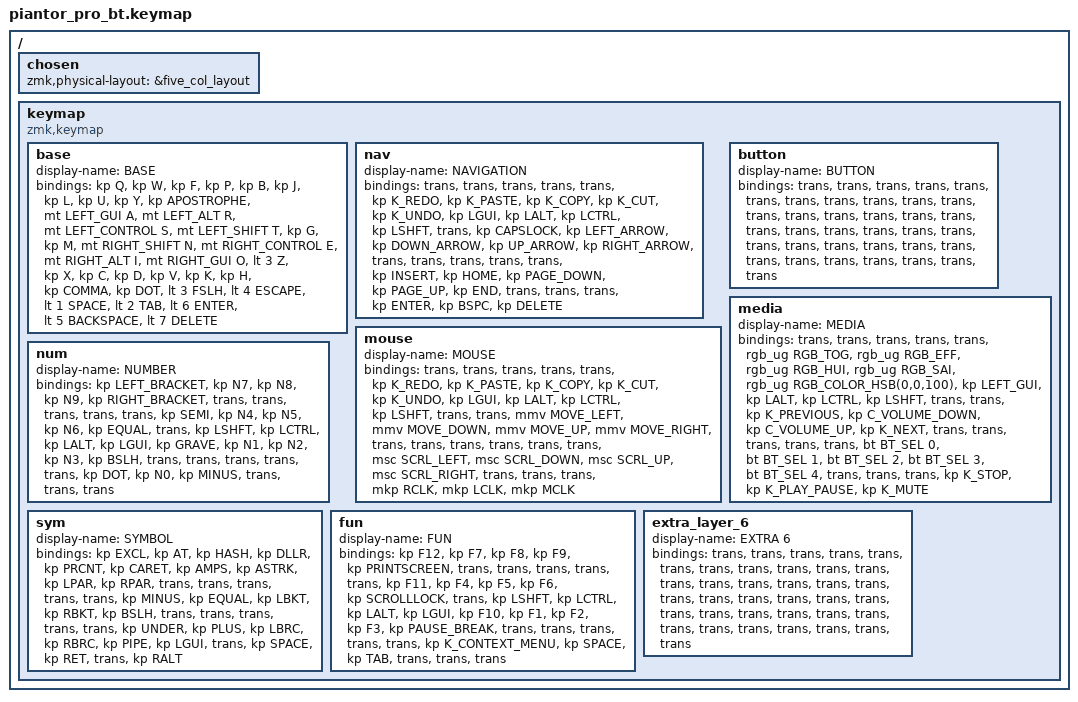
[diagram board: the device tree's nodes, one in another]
/*
 * Copyright (c) 2020 The ZMK Contributors
 *
 * SPDX-License-Identifier: MIT
 */

#include <behaviors.dtsi>
#include <dt-bindings/zmk/bt.h>
#include <dt-bindings/zmk/keys.h>
#include <dt-bindings/zmk/pointing.h>
#include <dt-bindings/zmk/rgb.h>

/ {
    chosen { zmk,physical-layout = &five_col_layout; };
};

/ {
    keymap {
        compatible = "zmk,keymap";

        base {
            display-name = "BASE";

            // --------------------------------------------------------------
            // |  Q  |  W  |  E  |  R  |  T  |  Y  |  U   |  I  |  O  |  P  |
            // |  A  |  S  |  D  |  F  |  G  |  H  |  J   |  K  |  L  |  ;  |
            // |  Z  |  X  |  C  |  V  |  B  |  N  |  M   |  ,  |  .  |  /  |
            //                    | GUI | LWR | SPC | ENT | RSE  | ALT |

            bindings = <
  &kp Q  &kp W  &kp F  &kp P  &kp B  &kp J  &kp L  &kp U  &kp Y  &kp APOSTROPHE      &mt LEFT_GUI A  &mt LEFT_ALT R  &mt LEFT_CONTROL S  &mt LEFT_SHIFT T  &kp G  &kp M  &mt RIGHT_SHIFT N  &mt RIGHT_CONTROL E  &mt RIGHT_ALT I  &mt RIGHT_GUI O      &lt 3 Z  &kp X  &kp C  &kp D  &kp V  &kp K  &kp H  &kp COMMA  &kp DOT  &lt 3 FSLH    &lt 4 ESCAPE  &lt 1 SPACE  &lt 2 TAB  &lt 6 ENTER  &lt 5 BACKSPACE  &lt 7 DELETE
            >;
        };

        nav {
            display-name = "NAVIGATION";
            bindings = <
  &trans  &trans  &trans  &trans  &trans  &kp K_REDO  &kp K_PASTE  &kp K_COPY  &kp K_CUT  &kp K_UNDO      &kp LGUI  &kp LALT  &kp LCTRL  &kp LSHFT  &trans  &kp CAPSLOCK  &kp LEFT_ARROW  &kp DOWN_ARROW  &kp UP_ARROW  &kp RIGHT_ARROW      &trans  &trans  &trans  &trans  &trans  &kp INSERT  &kp HOME  &kp PAGE_DOWN  &kp PAGE_UP  &kp END    &trans  &trans  &trans  &kp ENTER  &kp BSPC  &kp DELETE
            >;
        };

        mouse {
            display-name = "MOUSE";
            bindings = <
  &trans  &trans  &trans  &trans  &trans  &kp K_REDO  &kp K_PASTE  &kp K_COPY  &kp K_CUT  &kp K_UNDO      &kp LGUI  &kp LALT  &kp LCTRL  &kp LSHFT  &trans  &trans  &mmv MOVE_LEFT  &mmv MOVE_DOWN  &mmv MOVE_UP  &mmv MOVE_RIGHT      &trans  &trans  &trans  &trans  &trans  &trans  &msc SCRL_LEFT  &msc SCRL_DOWN  &msc SCRL_UP  &msc SCRL_RIGHT    &trans  &trans  &trans  &mkp RCLK  &mkp LCLK  &mkp MCLK
            >;
        };

        button {
            display-name = "BUTTON";
            bindings = <
  &trans  &trans  &trans  &trans  &trans  &trans  &trans  &trans  &trans  &trans      &trans  &trans  &trans  &trans  &trans  &trans  &trans  &trans  &trans  &trans      &trans  &trans  &trans  &trans  &trans  &trans  &trans  &trans  &trans  &trans    &trans  &trans  &trans  &trans  &trans  &trans
            >;
        };

        media {
            display-name = "MEDIA";
            bindings = <
  &trans  &trans  &trans  &trans  &trans  &rgb_ug RGB_TOG  &rgb_ug RGB_EFF  &rgb_ug RGB_HUI  &rgb_ug RGB_SAI  &rgb_ug RGB_COLOR_HSB(0,0,100)      &kp LEFT_GUI  &kp LALT  &kp LCTRL  &kp LSHFT  &trans  &trans  &kp K_PREVIOUS  &kp C_VOLUME_DOWN  &kp C_VOLUME_UP  &kp K_NEXT      &trans  &trans  &trans  &trans  &trans  &bt BT_SEL 0  &bt BT_SEL 1  &bt BT_SEL 2  &bt BT_SEL 3  &bt BT_SEL 4    &trans  &trans  &trans  &kp K_STOP  &kp K_PLAY_PAUSE  &kp K_MUTE
            >;
        };

        num {
            display-name = "NUMBER";

            // ---------------------------------------------------------------
            // |  1  |  2  |  3  |  4  |  5    |  6  |  7  |  8  |  9  |  0  |
            // | BT1 | BT2 | BT3 | BT4 | BT5   | LFT | DWN |  UP | RGT |     |
            // | BTCR| RGB | RST | BOOT| Unlock|     |     |     |     |     |
            //                    | GUI |     | SPC   | ENT |     | ALT |

            bindings = <
  &kp LEFT_BRACKET  &kp N7  &kp N8  &kp N9  &kp RIGHT_BRACKET  &trans  &trans  &trans  &trans  &trans      &kp SEMI  &kp N4  &kp N5  &kp N6  &kp EQUAL  &trans  &kp LSHFT  &kp LCTRL  &kp LALT  &kp LGUI      &kp GRAVE  &kp N1  &kp N2  &kp N3  &kp BSLH  &trans  &trans  &trans  &trans  &trans    &kp DOT  &kp N0  &kp MINUS  &trans  &trans  &trans
            >;
        };

        sym {
            display-name = "SYMBOL";

            // -------------------------------------------------------------
            // |  !  |  @  |  #  |  $  |  %  |  ^  |  &  |  *  |  (  |  )  |
            // |     |     |     |     |     |  -  |  =  |  [  |  ]  |  \  |
            // |     |     |     |     |     |  _  |  +  |  {  |  }  | "|" |
            //                    | GUI |     | SPC | ENT |     | ALT |

            bindings = <
  &kp EXCL  &kp AT  &kp HASH  &kp DLLR  &kp PRCNT  &kp CARET  &kp AMPS  &kp ASTRK  &kp LPAR  &kp RPAR      &trans  &trans  &trans  &trans  &trans  &kp MINUS  &kp EQUAL  &kp LBKT  &kp RBKT  &kp BSLH      &trans  &trans  &trans  &trans  &trans  &kp UNDER  &kp PLUS  &kp LBRC  &kp RBRC  &kp PIPE    &kp LGUI  &trans  &kp SPACE  &kp RET  &trans  &kp RALT
            >;
        };

        fun {
            display-name = "FUN";
            bindings = <
  &kp F12  &kp F7  &kp F8  &kp F9  &kp PRINTSCREEN  &trans  &trans  &trans  &trans  &trans      &kp F11  &kp F4  &kp F5  &kp F6  &kp SCROLLLOCK  &trans  &kp LSHFT  &kp LCTRL  &kp LALT  &kp LGUI      &kp F10  &kp F1  &kp F2  &kp F3  &kp PAUSE_BREAK  &trans  &trans  &trans  &trans  &trans    &kp K_CONTEXT_MENU  &kp SPACE  &kp TAB  &trans  &trans  &trans
            >;
        };

        extra_layer_6 {
            display-name = "EXTRA 6";
            bindings = <
  &trans  &trans  &trans  &trans  &trans  &trans  &trans  &trans  &trans  &trans      &trans  &trans  &trans  &trans  &trans  &trans  &trans  &trans  &trans  &trans      &trans  &trans  &trans  &trans  &trans  &trans  &trans  &trans  &trans  &trans    &trans  &trans  &trans  &trans  &trans  &trans
            >;
        };
    };
};
